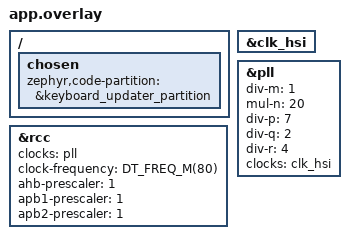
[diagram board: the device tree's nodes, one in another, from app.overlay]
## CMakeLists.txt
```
# SPDX-License-Identifier: Apache-2.0
cmake_minimum_required(VERSION 3.28.0)

set(BOARD_ROOT ${CMAKE_CURRENT_LIST_DIR}/../..)
list(APPEND DTS_ROOT ${CMAKE_CURRENT_LIST_DIR}/../../boards/ef800_keyboard)
find_package(Zephyr REQUIRED HINTS $ENV{ZEPHYR_BASE})
project(ef800_keyboard_updater)

target_sources(app PRIVATE
	src/main.c
	src/keyboard_updater_flash.c
	src/keyboard_updater_session.c
	src/keyboard_updater_transport.c
	${CMAKE_CURRENT_LIST_DIR}/../../shared/ef800_keyboard_update/ef800_keyboard_update_protocol.c
	${CMAKE_CURRENT_LIST_DIR}/../../shared/ef800_update/ef800_update.c
	${CMAKE_CURRENT_LIST_DIR}/../../shared/ef800_watchdog/ef800_watchdog.c
)

target_include_directories(app PRIVATE
	${CMAKE_CURRENT_LIST_DIR}/../../shared/ef800_keyboard_update
	${CMAKE_CURRENT_LIST_DIR}/../../shared/ef800_update
	${CMAKE_CURRENT_LIST_DIR}/../../shared/ef800_watchdog
)
```

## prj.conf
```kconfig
# SPDX-License-Identifier: Apache-2.0
CONFIG_I2C=y
CONFIG_I2C_TARGET=y
CONFIG_FLASH=y
CONFIG_FLASH_MAP=y
CONFIG_FLASH_PAGE_LAYOUT=y
CONFIG_WATCHDOG=y
CONFIG_REBOOT=y
CONFIG_USE_DT_CODE_PARTITION=y
CONFIG_MAIN_STACK_SIZE=1536
```

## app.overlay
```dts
/* SPDX-License-Identifier: Apache-2.0 */
/ {
	chosen {
		zephyr,code-partition = &keyboard_updater_partition;
	};
};

&clk_hsi {
	status = "okay";
};

&pll {
	div-m = <1>;
	mul-n = <20>;
	div-p = <7>;
	div-q = <2>;
	div-r = <4>;
	clocks = <&clk_hsi>;
	status = "okay";
};

&rcc {
	clocks = <&pll>;
	clock-frequency = <DT_FREQ_M(80)>;
	ahb-prescaler = <1>;
	apb1-prescaler = <1>;
	apb2-prescaler = <1>;
};
```

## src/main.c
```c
/* SPDX-License-Identifier: Apache-2.0 */
#include <errno.h>
#include <stdbool.h>
#include <stddef.h>
#include <stdint.h>

#include <zephyr/kernel.h>
#include <zephyr/sys/reboot.h>

#include "ef800_watchdog.h"
#include "keyboard_updater_transport.h"
#include "keyboard_updater_session.h"

int main(void)
{
	uint8_t incoming[EF800_KB_UPDATE_REQUEST_MAX];
	uint8_t outgoing[EF800_KB_UPDATE_RESPONSE_MAX];
	size_t incoming_length;
	size_t outgoing_length;
	bool incoming_version;
	bool timed_out;
	bool overflow;
	bool reboot_after_response;

	if (ef800_watchdog_inherit() != 0) {
		return -EIO;
	}
	if (ef800_keyboard_updater_transport_init() != 0) {
		return -ENODEV;
	}

	for (;;) {
		if (ef800_keyboard_updater_request_take(incoming, &incoming_length,
				&incoming_version, &timed_out, &overflow)) {
			(void)ef800_keyboard_updater_session_process(incoming, incoming_length,
				incoming_version, timed_out, overflow, outgoing,
				&outgoing_length, &reboot_after_response);
			(void)ef800_keyboard_updater_response_submit(outgoing,
				outgoing_length, reboot_after_response);
		}
		if (ef800_keyboard_updater_reboot_take()) {
			sys_reboot(SYS_REBOOT_COLD);
		}
		(void)ef800_watchdog_feed();
		k_msleep(1U);
	}
}
```

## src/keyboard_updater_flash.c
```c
/* SPDX-License-Identifier: Apache-2.0 */

#include "keyboard_updater_flash.h"

#include <errno.h>

#include <zephyr/sys/util.h>

#include "ef800_update.h"
#include "ef800_watchdog.h"

#define BOOT_PARTITION_ID PARTITION_ID(keyboard_boot_partition)
#define APP_PARTITION_ID PARTITION_ID(keyboard_app_partition)

BUILD_ASSERT(PARTITION_OFFSET(keyboard_boot_partition) == 0x00000000U);
BUILD_ASSERT(PARTITION_SIZE(keyboard_boot_partition) == 0x00008000U);
BUILD_ASSERT(PARTITION_OFFSET(keyboard_app_partition) == 0x00008000U);
BUILD_ASSERT(PARTITION_SIZE(keyboard_app_partition) == 0x00030000U);
BUILD_ASSERT(PARTITION_OFFSET(keyboard_updater_partition) == 0x00038000U);
BUILD_ASSERT(PARTITION_SIZE(keyboard_updater_partition) == 0x00008000U);

int ef800_keyboard_updater_flash_open(enum ef800_kb_update_target target,
				      const struct flash_area **area)
{
	uint8_t partition_id;
	uint32_t base;
	uint32_t size;
	int result;

	if (area == NULL || !ef800_kb_update_service_target_valid(
		    EF800_KB_UPDATE_SERVICE_UPDATER, target) ||
	    !ef800_kb_update_target_range(target, &base, &size)) {
		return -EACCES;
	}
	ARG_UNUSED(base);

	switch (target) {
	case EF800_KB_UPDATE_TARGET_BOOTLOADER:
		partition_id = BOOT_PARTITION_ID;
		break;
	case EF800_KB_UPDATE_TARGET_APPLICATION:
		partition_id = APP_PARTITION_ID;
		break;
	default:
		return -EACCES;
	}
	result = flash_area_open(partition_id, area);
	if (result != 0) {
		return result;
	}
	if (!flash_area_device_is_ready(*area) || (*area)->fa_size != size) {
		(void)flash_area_close(*area);
		*area = NULL;
		return -ENODEV;
	}
	return 0;
}

int ef800_keyboard_updater_flash_erase_page(const struct flash_area *area,
					    uint32_t relative_page)
{
	int result;

	if (area == NULL || area->fa_size % EF800_KB_UPDATE_PAGE_SIZE != 0U ||
	    relative_page >= area->fa_size / EF800_KB_UPDATE_PAGE_SIZE) {
		return -EINVAL;
	}
	result = flash_area_erase(area,
		relative_page * EF800_KB_UPDATE_PAGE_SIZE,
		EF800_KB_UPDATE_PAGE_SIZE);
	(void)ef800_watchdog_feed();
	return result;
}

int ef800_keyboard_updater_flash_read(const struct flash_area *area,
				     uint32_t offset, void *data, size_t length)
{
	if (area == NULL || (data == NULL && length != 0U) ||
	    offset > area->fa_size || length > area->fa_size - offset) {
		return -EINVAL;
	}
	return flash_area_read(area, offset, data, length);
}

int ef800_keyboard_updater_flash_write(const struct flash_area *area,
				      uint32_t offset, const void *data,
				      size_t length)
{
	if (area == NULL || (data == NULL && length != 0U) ||
	    offset > area->fa_size || length > area->fa_size - offset) {
		return -EINVAL;
	}
	return flash_area_write(area, offset, data, length);
}

void ef800_keyboard_updater_flash_close(const struct flash_area *area)
{
	if (area != NULL) {
		flash_area_close(area);
	}
}
```

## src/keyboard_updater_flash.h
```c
/* SPDX-License-Identifier: Apache-2.0 */

#ifndef EF800_KEYBOARD_UPDATER_FLASH_H
#define EF800_KEYBOARD_UPDATER_FLASH_H

#include <stddef.h>
#include <stdint.h>

#include <zephyr/storage/flash_map.h>

#include "ef800_keyboard_update_protocol.h"

int ef800_keyboard_updater_flash_open(enum ef800_kb_update_target target,
				      const struct flash_area **area);
int ef800_keyboard_updater_flash_erase_page(const struct flash_area *area,
					    uint32_t relative_page);
int ef800_keyboard_updater_flash_read(const struct flash_area *area,
				     uint32_t offset, void *data, size_t length);
int ef800_keyboard_updater_flash_write(const struct flash_area *area,
				      uint32_t offset, const void *data,
				      size_t length);
void ef800_keyboard_updater_flash_close(const struct flash_area *area);

#endif /* EF800_KEYBOARD_UPDATER_FLASH_H */
```

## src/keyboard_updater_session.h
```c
/* SPDX-License-Identifier: Apache-2.0 */

#ifndef EF800_KEYBOARD_UPDATER_SESSION_H
#define EF800_KEYBOARD_UPDATER_SESSION_H

#include <stdbool.h>
#include <stddef.h>
#include <stdint.h>

#include "ef800_keyboard_update_protocol.h"

int ef800_keyboard_updater_session_process(
	const uint8_t *request, size_t request_length, bool is_version,
	bool timed_out, bool overflow,
	uint8_t response[EF800_KB_UPDATE_RESPONSE_MAX], size_t *response_length,
	bool *reboot_after_response);

#endif /* EF800_KEYBOARD_UPDATER_SESSION_H */
```

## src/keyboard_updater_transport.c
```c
/* SPDX-License-Identifier: Apache-2.0 */

#include "keyboard_updater_transport.h"

#include <errno.h>
#include <string.h>

#include <zephyr/device.h>
#include <zephyr/devicetree.h>
#include <zephyr/drivers/i2c.h>
#include <zephyr/kernel.h>
#include <zephyr/sys/atomic.h>

#define UPDATER_I2C_ADDRESS EF800_KEYBOARD_UPDATER_I2C_ADDRESS

static const struct device *const i2c_target =
	DEVICE_DT_GET(DT_NODELABEL(i2c1));
static uint8_t request_frame[EF800_KB_UPDATE_REQUEST_MAX] __aligned(4);
static size_t request_length;
static uint32_t last_byte_ms;
static bool request_is_version;
static bool request_timed_out;
static bool request_overflow;
static bool write_transaction;
static bool read_transaction;
static uint8_t response[EF800_KB_UPDATE_RESPONSE_MAX] __aligned(4);
static size_t response_length;
static size_t response_position;
static atomic_t request_busy;
static atomic_t request_pending;
static atomic_t response_ready;
static atomic_t reboot_after_response;
static atomic_t reboot_pending;

static int write_requested(struct i2c_target_config *config)
{
	ARG_UNUSED(config);
	if (atomic_get(&request_busy) != 0) {
		return -EBUSY;
	}
	atomic_set(&request_busy, 1);
	atomic_set(&response_ready, 0);
	request_length = 0U;
	request_is_version = false;
	request_timed_out = false;
	request_overflow = false;
	last_byte_ms = k_uptime_get_32();
	write_transaction = true;
	read_transaction = false;
	return 0;
}

static int write_received(struct i2c_target_config *config, uint8_t byte)
{
	uint32_t now = k_uptime_get_32();

	ARG_UNUSED(config);
	if (!ef800_kb_update_frame_timing_valid(last_byte_ms, now)) {
		request_timed_out = true;
	}
	last_byte_ms = now;
	if (request_length == 0U && !request_is_version &&
	    byte == EF800_KB_UPDATE_VERSION_COMMAND) {
		request_is_version = true;
		return 0;
	}
	if (request_is_version || request_length >= sizeof(request_frame)) {
		request_overflow = true;
		return 0;
	}
	request_frame[request_length++] = byte;
	return 0;
}

static int read_requested(struct i2c_target_config *config, uint8_t *byte)
{
	ARG_UNUSED(config);
	read_transaction = true;
	write_transaction = false;
	response_position = 0U;
	if (atomic_get(&response_ready) == 0) {
		*byte = EF800_KB_PROTOCOL_BUSY;
		response_length = 1U;
		response_position = 1U;
		return 0;
	}
	if (response_length == 0U) {
		*byte = EF800_KB_PROTOCOL_NACK;
		response_length = 1U;
		response_position = 1U;
		return 0;
	}
	*byte = response[response_position++];
	return 0;
}

static int read_processed(struct i2c_target_config *config, uint8_t *byte)
{
	ARG_UNUSED(config);
	if (response_position < response_length) {
		*byte = response[response_position++];
	} else {
		*byte = 0xFFU;
	}
	return 0;
}

static int i2c_stop(struct i2c_target_config *config)
{
	ARG_UNUSED(config);
	if (write_transaction) {
		write_transaction = false;
		atomic_set(&request_pending, 1);
	} else if (read_transaction) {
		read_transaction = false;
		if (response_position >= response_length) {
			atomic_set(&response_ready, 0);
			if (atomic_cas(&reboot_after_response, 1, 0)) {
				atomic_set(&reboot_pending, 1);
			}
		}
	}
	return 0;
}

static const struct i2c_target_callbacks callbacks = {
	.write_requested = write_requested,
	.write_received = write_received,
	.read_requested = read_requested,
	.read_processed = read_processed,
	.stop = i2c_stop,
};

static struct i2c_target_config config = {
	.address = UPDATER_I2C_ADDRESS,
	.callbacks = &callbacks,
};

int ef800_keyboard_updater_transport_init(void)
{
	if (!device_is_ready(i2c_target)) {
		return -ENODEV;
	}
	return i2c_target_register(i2c_target, &config);
}

bool ef800_keyboard_updater_request_take(
	uint8_t out[EF800_KB_UPDATE_REQUEST_MAX], size_t *out_length,
	bool *is_version, bool *timed_out, bool *overflow)
{
	if (out == NULL || out_length == NULL || is_version == NULL ||
		timed_out == NULL || overflow == NULL ||
		!atomic_cas(&request_pending, 1, 0)) {
		return false;
	}
	memcpy(out, request_frame, request_length);
	*out_length = request_length;
	*is_version = request_is_version;
	*timed_out = request_timed_out;
	*overflow = request_overflow;
	return true;
}

int ef800_keyboard_updater_response_submit(
	const uint8_t data[EF800_KB_UPDATE_RESPONSE_MAX], size_t length,
	bool reboot)
{
	if (data == NULL || length > sizeof(response)) {
		return -EINVAL;
	}
	memcpy(response, data, length);
	response_length = length;
	response_position = 0U;
	if (reboot) {
		atomic_set(&reboot_after_response, 1);
	}
	atomic_set(&response_ready, 1);
	atomic_set(&request_busy, 0);
	return 0;
}

bool ef800_keyboard_updater_reboot_take(void)
{
	return atomic_cas(&reboot_pending, 1, 0);
}
```

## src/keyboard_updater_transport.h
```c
/* SPDX-License-Identifier: Apache-2.0 */
/** @file
 * @brief Queue keyboard updater requests and responses across the I2C transport.
 */

#ifndef EF800_KEYBOARD_UPDATER_TRANSPORT_H
#define EF800_KEYBOARD_UPDATER_TRANSPORT_H

#include <stdbool.h>
#include <stddef.h>
#include <stdint.h>

#include "ef800_keyboard_update_protocol.h"

/** @brief Initialize the updater request/response transport.
 * @return 0 on success; negative errno if transport setup fails.
 */
int ef800_keyboard_updater_transport_init(void);

/** @brief Consume a pending request and its capture metadata.
 * @param request Receives request bytes up to the protocol maximum.
 * @param request_length Receives request byte count.
 * @param is_version Receives whether this is a version query.
 * @param timed_out Receives capture timeout state.
 * @param overflow Receives capture overflow state.
 * @return True if a request was consumed; otherwise false.
 */
bool ef800_keyboard_updater_request_take(
	uint8_t request[EF800_KB_UPDATE_REQUEST_MAX], size_t *request_length,
	bool *is_version, bool *timed_out, bool *overflow);

/** @brief Submit a response and indicate whether reboot follows transmission.
 * @param response Complete response frame.
 * @param response_length Number of response bytes.
 * @param reboot_after_response True to reboot after the transport sends it.
 * @return 0 on submission; negative errno if response cannot be queued.
 */
int ef800_keyboard_updater_response_submit(
	const uint8_t response[EF800_KB_UPDATE_RESPONSE_MAX], size_t response_length,
	bool reboot_after_response);

/** @brief Consume a pending reboot request.
 * @return True if reboot was requested, otherwise false.
 */
bool ef800_keyboard_updater_reboot_take(void);

#endif /* EF800_KEYBOARD_UPDATER_TRANSPORT_H */
```
